# CortexM-SysTick register map
The system timer of an Arm Cortex-M core
Registers are 32-bit, read-write, no defined reset value unless marked. A register's access mark holds for its fields unless they carry their own. Offsets are from the block's base; lines under a group give offsets from that group; [hi:lo] are bit positions; {n}, {i} and the like mark numbered series; 'fields as' and 'values as' point back to an identical list; <NAME> marks a mode.

## Memory map
0xE000E010 SYST — SysTick: a 24-bit down counter that can interrupt

## SYST — SysTick: a 24-bit down counter that can interrupt
Base 0xE000E010
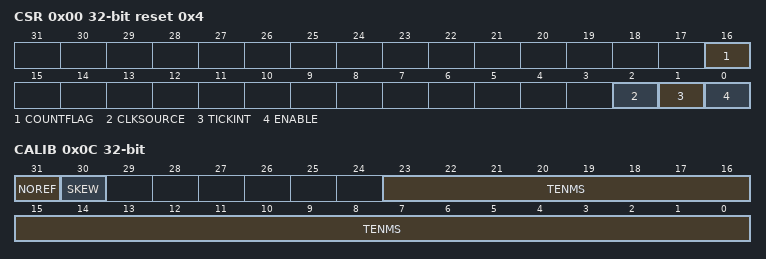
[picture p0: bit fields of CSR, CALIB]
0x00 CSR reset 0x4 read-clears — Control and status
  [16] COUNTFLAG ro — The counter reached 0 since the last read
  [2] CLKSOURCE — Clock source
    0=External; 1=Processor
  [1] TICKINT — Interrupt when the counter reaches 0
  [0] ENABLE — Counter enable
0x04 RVR — Reload value
  [23:0] RELOAD
0x08 CVR — Current value (a write clears it)
  [23:0] CURRENT
0x0C CALIB ro — Calibration
  [31] NOREF, [30] SKEW, [23:0] TENMS
